# R7FA2L1AB register map
Vendor: Renesas Electronics Corporation; Series: RA2L1; File version: 0.50.00
CPU: CM23 r1p0, little endian, MPU, no FPU, VTOR, 2 interrupt priority bits, 32 interrupts
Registers are 8-bit, read-write, reset 0x0 unless marked. A register's access mark holds for its fields unless they carry their own. Offsets are from the block's base; [hi:lo] are bit positions; {n}, {i} and the like mark numbered series; 'fields as' and 'values as' point back to an identical list.

## KINT — Key Interrupt Function
Base 0x40080000
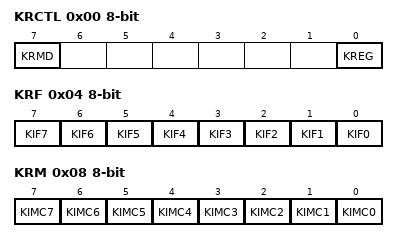
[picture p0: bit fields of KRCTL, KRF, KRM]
0x00 KRCTL — Key Return Control Register
  [7] KRMD — Usage of Key Interrupt Flags (KRF.KIF0 to KRF.KIF7)
    0=Do not use key interrupt flags; 1=Use key interrupt flags
  [0] KREG — Detection Edge Selection (KR00 to KR07)
    0=Falling edge; 1=Rising edge
0x04 KRF — Key Return Flag Register
  [all] fields
    0=No interrupt detected; 1=Interrupt detected
  [n] KIF{n} (n=0..7) — Key Interrupt Flag n
0x08 KRM — Key Return Mode Register
  [all] fields
    0=Do not detect key interrupt signals; 1=Detect key interrupt signals
  [n] KIMC{n} (n=0..7) — Key Interrupt Mode Control n

## AGT0 — Low Power Asynchronous General Purpose Timer 0
Base 0x40084000
Same registers: AGT1 0x40084100
0x00 AGT 16-bit reset 0xFFFF — AGT Counter Register
0x02 AGTCMA 16-bit reset 0xFFFF — AGT Compare Match A Register
0x04 AGTCMB 16-bit reset 0xFFFF — AGT Compare Match B Register
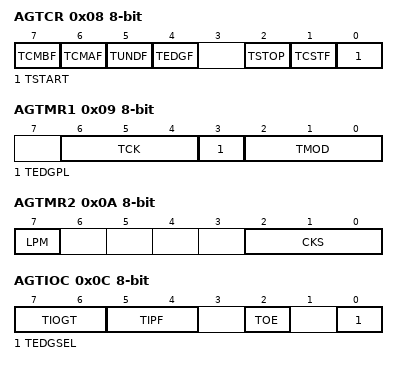
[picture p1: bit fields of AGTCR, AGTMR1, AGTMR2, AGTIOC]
0x08 AGTCR — AGT Control Register
  [7] TCMBF — Compare Match B Flag
    0=No match; 1=Match
  [6] TCMAF — Compare Match A Flag
    0=No match; 1=Match
  [5] TUNDF — Underflow Flag
    0=No underflow; 1=Underflow
  [4] TEDGF — Active Edge Judgment Flag
    0=No active edge received; 1=Active edge received
  [2] TSTOP wo — AGT Count Forced Stop
    0=Writing is invalid; 1=The count is forcibly stopped
  [1] TCSTF ro — AGT Count Status Flag
    0=Count stopped; 1=Count in progress
  [0] TSTART — AGT Count Start
    0=Count stops; 1=Count starts
0x09 AGTMR1 — AGT Mode Register 1
  [6:4] TCK — Count Source
    0=PCLKB; 1=PCLKB/8; 3=PCLKB/2; 4=Divided clock AGTLCLK specified by CKS[2:0] bits in the AGTMR2 register; 5=Underflow event signal from AGT0; 6=Divided clock AGTSCLK specified by CKS[2:0] bits in the AGTMR2 register; other=Others (Setting prohibited)
  [3] TEDGPL — Edge Polarity
    0=Single-edge; 1=Both-edge
  [2:0] TMOD — Operating Mode
    0=Timer mode; 1=Pulse output mode; 2=Event counter mode; 3=Pulse width measurement mode; 4=Pulse period measurement mode; other=Others (Setting prohibited)
0x0A AGTMR2 — AGT Mode Register 2
  [7] LPM — Low Power Mode
    0=Normal mode; 1=Low power mode
  [2:0] CKS — AGTLCLK or AGTSCLK Count Source Clock Frequency Division Ratio
    0=1/1; 1=1/2; 2=1/4; 3=1/8; 4=1/16; 5=1/32; 6=1/64; 7=1/128
0x0C AGTIOC — AGT I/O Control Register
  [7:6] TIOGT — Count Control
    0=Event is always counted; 1=Event is counted during polarity period specified for AGTEEn; other=Others (Setting prohibited)
  [5:4] TIPF — Input Filter
    0=No filter; 1=Filter sampled at PCLKB; 2=Filter sampled at PCLKB/8; 3=Filter sampled at PCLKB/32
  [2] TOE — AGTOn Output Enable
    0=AGTOn output disabled; 1=AGTOn output enabled
  [0] TEDGSEL — I/O Polarity Switch
0x0D AGTISR — AGT Event Pin Select Register
  [2] EEPS — AGTEEn Polarity Selection
    0=An event is counted during the low-level period; 1=An event is counted during the high-level period
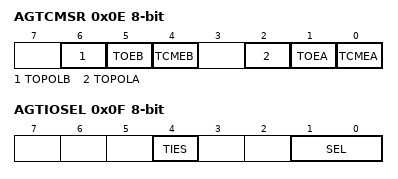
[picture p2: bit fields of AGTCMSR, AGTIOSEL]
0x0E AGTCMSR — AGT Compare Match Function Select Register
  [6] TOPOLB — AGTOBn Polarity Select
    0=AGTOBn output is started on low; 1=AGTOBn output is started on high
  [5] TOEB — AGTOBn Output Enable
    0=AGTOBn output disabled; 1=AGTOBn output enabled
  [4] TCMEB — Compare Match B Register Enable
    0=Compare match B register disabled; 1=Compare match B register enabled
  [2] TOPOLA — AGTOAn Polarity Select
    0=AGTOAn output is started on low; 1=AGTOAn output is started on high
  [1] TOEA — AGTOAn Output Enable
    0=AGTOAn output disabled; 1=AGTOAn output enabled
  [0] TCMEA — Compare Match A Register Enable
    0=Compare match A register disabled; 1=Compare match A register enabled
0x0F AGTIOSEL — AGT Pin Select Register
  [4] TIES — AGTIOn Input Enable
    0=External event input is disabled during Software Standby mode; 1=External event input is enabled during Software Standby mode
  [1:0] SEL — AGTIOn Pin Select
    0=Select the AGTIOn except for the following pins; 1=Setting prohibited; 2=Select the P402/AGTIOn P402/AGTIOn as input only. It cannot be used for output.; 3=Select the P403/AGTIOn P403/AGTIOn as input only. It cannot be used for output.

## ACMPLP — Low-Power Analog Comparator
Base 0x40085E00
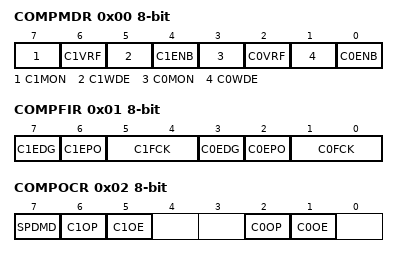
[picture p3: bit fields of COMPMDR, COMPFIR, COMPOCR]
0x00 COMPMDR — ACMPLP Mode Setting Register
  [7] C1MON ro — ACMPLP1 Monitor Flag
  [6] C1VRF — ACMPLP1 Reference Voltage Selection
    0=Select CMPREF1 input as ACMPLP1 reference voltage; 1=Select internal reference voltage (Vref) as ACMPLP1 reference voltage
  [5] C1WDE — ACMPLP1 Window Function Mode Enable
    0=Disable ACMPLP1 window function mode; 1=Enable ACMPLP1 window function mode
  [4] C1ENB — ACMPLP1 Operation Enable
    0=Disable ACMPLP1 operation; 1=Enable ACMPLP1 operation
  [3] C0MON ro — ACMPLP0 Monitor Flag
  [2] C0VRF — ACMPLP0 Reference Voltage Selection
    0=Select CMPREF0 input as ACMPLP0 reference voltage; 1=Select internal reference voltage (Vref) as ACMPLP0 reference voltage
  [1] C0WDE — ACMPLP0 Window Function Mode Enable
    0=Disable window function for ACMPLP0; 1=Enable window function for ACMPLP0
  [0] C0ENB — ACMPLP0 Operation Enable
    0=Disable comparator channel ACMPLP0; 1=Enable comparator channel ACMPLP0
0x01 COMPFIR — ACMPLP Filter Control Register
  [7] C1EDG — ACMPLP1 Edge Detection Selection
    0=Interrupt and ELC event request by one-edge detection; 1=Interrupt and ELC event request by both-edge detection
  [6] C1EPO — ACMPLP1 Edge Polarity Switching
    0=Interrupt and ELC event request on rising edge; 1=Interrupt and ELC event request on falling edge
  [5:4] C1FCK — ACMPLP1 Filter Select
    0=No Sampling (bypass); 1=Sampling at PCLKB; 2=Sampling at PCLKB/8; 3=Sampling at PCLKB/32
  [3] C0EDG — ACMPLP0 Edge Detection Selection
    values as C1EDG
  [2] C0EPO — ACMPLP0 Edge Polarity Switching
    values as C1EPO
  [1:0] C0FCK — ACMPLP0 Filter Select
    values as C1FCK
0x02 COMPOCR — ACMPLP Output Control Register
  [7] SPDMD — ACMPLP0/ACMPLP1 Speed Selection
    0=Low-speed mode; 1=High-speed mode
  [6] C1OP — ACMPLP1 VCOUT Output Polarity Selection
    0=Non-inverted; 1=Inverted
  [5] C1OE — ACMPLP1 VCOUT Pin Output Enable
    0=Disabled; 1=Enabled
  [2] C0OP — ACMPLP0 VCOUT Output Polarity Selection
    0=Non-inverted; 1=Inverted
  [1] C0OE — ACMPLP0 VCOUT Pin Output Enable
    0=Disabled; 1=Enabled

## FLCN — Flash I/O Registers
Base 0x407EC000
0x90 DFLCTL — Data Flash Enable Register
  [0] DFLEN — Data Flash enable select
    0=Disable Data Flash (not available); 1=Enable Data Flash (accessible)
0x228 TSCDRL ro reset not defined — Temperature Sensor Calibration Data Register L
  [7:0] TSCDRL — Temperature Sensor Calibration Data
0x229 TSCDRH ro reset not defined — Temperature Sensor Calibration Data Register H
  [7:0] TSCDRH — Temperature Sensor Calibration Data
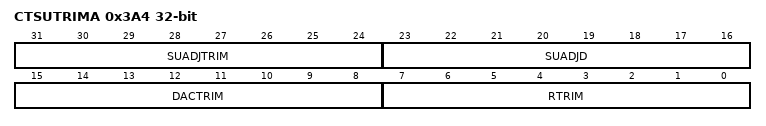
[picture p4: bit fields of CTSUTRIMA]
0x3A4 CTSUTRIMA 32-bit reset not defined — CTSU Trimming Register A
  [31:24] SUADJTRIM — CTSU Current DAC Matching Coefficient Adjustment 2
  [23:16] SUADJD — CTSU SUCLK Frequency Adjustment
  [15:8] DACTRIM — CTSU Current DAC Matching Coefficient Adjustment 1
  [7:0] RTRIM — CTSU Reference Resistance Adjustment
0x3FC4 FLDWAITR — Memory Wait Cycle Control Register for Data Flash
  [0] FLDWAIT1 — Memory Wait Cycle Select for Data Flash
    0=1 wait access (Default); 1=2 wait access
0x3FC8 PFBER — Prefetch Buffer Enable Register
  [0] PFBE — Prefetch Buffer Enable bit
    0=FLPF is disabled; 1=FLPF is enabled
